# D1H register map
Vendor: Allwinner; File version: 1.0
Registers are 32-bit, read-write, reset 0x0 unless marked. A register's access mark holds for its fields unless they carry their own. Offsets are from the block's base; [hi:lo] are bit positions; {n}, {i} and the like mark numbered series.

## RISCV_CFG — RISC-V System Configuration
Base 0x06010000
0x04 riscv_sta_add0 — RISCV Start Address0 Register
0x08 riscv_sta_add1 — RISCV Start Address1 Register
  [7:0] sta_add_h — Start Address High 8-bit
0x10 rf1p_cfg — RF1P Configuration Register
  [7:0] rf1p_cfg — RF1P Configuration
0x1C rom_cfg — ROM Configuration Register
  [7:0] rom_cfg — ROM Configuration
0x20 wakeup_en — Wakeup Enable Register
  [0] wp_en — Wakeup Enable
{0x24+4i} wakeup_mask{i} (i=0..4)
0x40 ts_tmode_sel — Timestamp Test Mode Select Register
  [0] ts_test_mode_en — Timestamp Test Mode Enable
    0=NORMAL; 1=TEST
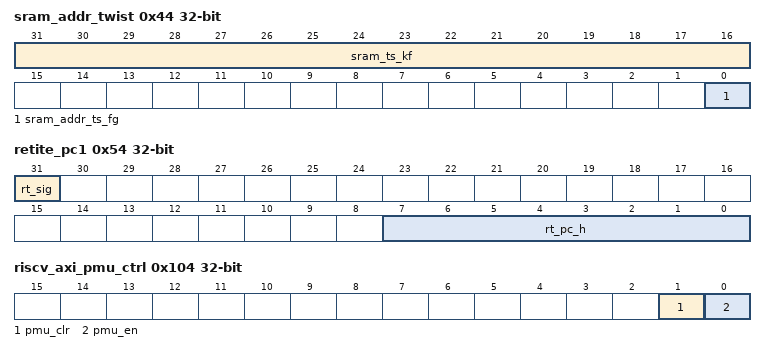
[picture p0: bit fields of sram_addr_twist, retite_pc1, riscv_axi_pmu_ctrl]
0x44 sram_addr_twist — SRAM Address Twist Register
  [31:16] sram_ts_kf wo — SRAM Twist Keyfield
  [0] sram_addr_ts_fg — SRAM Address Twist Flag
0x48 work_mode ro
  [1:0] wm_sta — Work Mode Status
    0=NORMAL; 1=LOW_POWER; 2=DEBUG
0x50 retite_pc0 ro — Retire PC0 Register
0x54 retite_pc1 ro — Retire PC1 Register
  [31] rt_sig — Retire Signal
    0=NOT_HAVE; 1=HAVE
  [7:0] rt_pc_h — Retire PC[39:32]
{0x60+4i} irq_mode{i} (i=0..4)
0x104 riscv_axi_pmu_ctrl — RISCV AXI PMU Control Register
  [1] pmu_clr write-clears — PMU Clear
    0=NO_OPERATION; 1=CLEARED
  [0] pmu_en — PMU Enable
    0=DISABLED; 1=ENABLED
0x108 riscv_axi_pmu_prd — RISCV AXI PMU Period Register
0x10C riscv_axi_pmu_lat_rd ro — RISCV AXI PMU Read Latency Register
0x110 riscv_axi_pmu_lat_wr ro — RISCV AXI PMU Write Latency Register
0x114 riscv_axi_pmu_req_rd ro — RISCV AXI PMU Read Request Register
0x118 riscv_axi_pmu_req_wr ro — RISCV AXI PMU Write Request Register
0x11C riscv_axi_pmu_bw_rd ro — RISCV AXI PMU Read Bandwidth Register
0x120 riscv_axi_pmu_bw_wr ro — RISCV AXI PMU Write Bandwidth Register

## CLINT — Core-Local Interruptor
Base 0x14000000
0x00 msip range 0..1 — MSIP Register for hart 0
0x4000 mtimecmpl — MTIMECMPL Register for hart 0
0x4004 mtimecmph — MTIMECMPH Register for hart 0
0xBFF8 mtime 64-bit ro (reset mask 0xFFFFFFFF) — MTIME . REF: opensbi
0xC000 ssip range 0..1 — SSIP Register for hart 0
0xD000 stimecmpl — STIMECMPL Register for hart 0
0xD004 stimecmph — STIMECMPH Register for hart 0

## TIMER — Timer Module, includes timer0, timer1, watchdog and audio video synchronization
Base 0x02050000
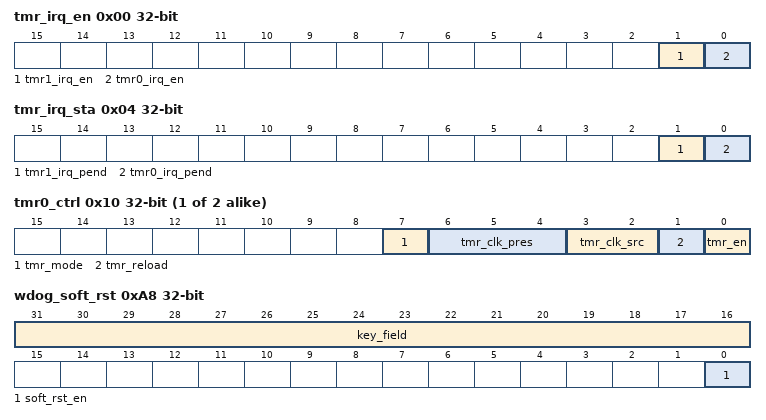
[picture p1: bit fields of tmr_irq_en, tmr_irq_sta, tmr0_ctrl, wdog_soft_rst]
0x00 tmr_irq_en — Timer IRQ Enable Register
  [1] tmr1_irq_en
    0=DISABLED; 1=ENABLED
  [0] tmr0_irq_en
    0=DISABLED; 1=ENABLED
0x04 tmr_irq_sta — Timer Status Register
  [1] tmr1_irq_pend
    0=NO_EFFECT; 1=PENDING (Indicates that the interval value of the timer 1 is reached. Write 1 to clear the pending status.)
  [0] tmr0_irq_pend
    0=NO_EFFECT; 1=PENDING (Indicates that the interval value of the timer 0 is reached. Write 1 to clear the pending status.)
{0x10+0x10*i} tmr{i}_ctrl (i=0..1) — Timer IRQ Enable Register
  [7] tmr_mode
    0=PERIODIC; 1=SINGLE_COUNTING
  [6:4] tmr_clk_pres
    0=P1; 1=P2; 2=P4; 3=P8; 4=P16; 5=P32; 6=P64; 7=P128
  [3:2] tmr_clk_src
    0=LOSC; 1=OSC24_M
  [1] tmr_reload
    0=NO_EFFECT; 1=RELOAD
  [0] tmr_en
    0=STOP_PAUSE; 1=START
{0x14+0x10*i} tmr{i}_intv_value (i=0..1) — Timer Interval Value Register
{0x18+0x10*i} tmr{i}_cur_value (i=0..1) — Timer Current Value Register
0xA0 wdog_irq_en — Watchdog IRQ Enable Register
  [0] wdog_irq_en
    0=DISABLED; 1=ENABLED
0xA4 wdog_irq_sta — Watchdog Status Register
  [0] wdog_irq_pend
    0=NO_EFFECT; 1=PENDING (Indicates that the interval value of the watchdog is reached.)
0xA8 wdog_soft_rst — Watchdog Software Reset Register
  [31:16] key_field wo
  [0] soft_rst_en — Soft Reset Enable
    0=DEASSERT; 1=RESET
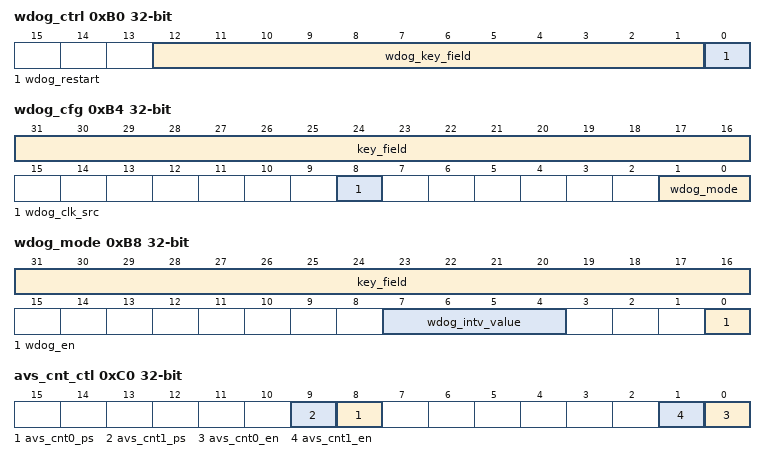
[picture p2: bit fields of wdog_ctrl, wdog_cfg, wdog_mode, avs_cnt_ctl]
0xB0 wdog_ctrl — Watchdog Control Register
  [12:1] wdog_key_field wo — Watchdog Key Field
  [0] wdog_restart write-1-sets — Watchdog Restart
    0=NO_EFFECT; 1=RESTART
0xB4 wdog_cfg — Watchdog Configuration Register
  [31:16] key_field wo
  [8] wdog_clk_src — Select the clock source for the watchdog.
    0=HOSC_32K; 1=LOSC_32K
  [1:0] wdog_mode — Configure the operating mode for the watchdog
    1=WHOLD_SYSTEM; 2=ONLY_INTERRUPT
0xB8 wdog_mode — Watchdog Mode Register
  [31:16] key_field wo
  [7:4] wdog_intv_value — Watchdog Interval Value
    0=C16000; 1=C32000; 2=C64000; 3=C96000; 4=C128000; 5=C160000; 6=C192000; 7=C256000; 8=C320000; 9=C384000; 10=C448000; 11=C512000
  [0] wdog_en — Watchdog Enable
    0=NO_EFFECT; 1=ENABLE
0xBC wdog_output_cfg — Watchdog Output Configuration Register
  [11:0] wdog_output_config — Configure the valid time for the watchdog reset signal.
0xC0 avs_cnt_ctl — AVS Counter Control Register
  [n+8] avs_cnt{n}_ps (n=0..1) — Audio Video Sync Counter Pause Control
    0=NOT_PAUSE; 1=PAUSE
  [n] avs_cnt{n}_en (n=0..1) — Audio Video Sync Counter Enable
    0=DISABLED; 1=ENABLED
0xC4 avs_cnt0 — AVS Counter 0 Register
0xC8 avs_cnt1 — AVS Counter 1 Register
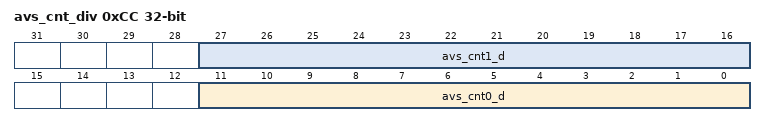
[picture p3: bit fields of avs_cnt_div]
0xCC avs_cnt_div — AVS Counter Divisor Register
  [16n+11:16n] avs_cnt{n}_d (n=0..1) — The divisor factor of AVS
